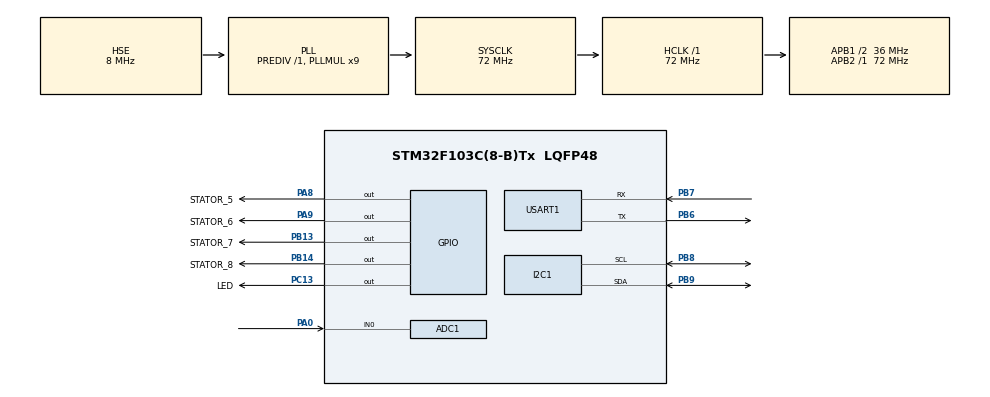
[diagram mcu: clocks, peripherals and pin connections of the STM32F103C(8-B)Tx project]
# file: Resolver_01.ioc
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ADC1.Channel-0\#ChannelRegularConversion=ADC_CHANNEL_0
ADC1.ExternalTrigConv=ADC_EXTERNALTRIGCONV_T3_TRGO
ADC1.NbrOfConversionFlag=1
ADC1.Rank-0\#ChannelRegularConversion=1
ADC1.SamplingTime-0\#ChannelRegularConversion=ADC_SAMPLETIME_1CYCLE_5
ADC1.master=1
Dma.ADC1.1.Direction=DMA_PERIPH_TO_MEMORY
Dma.ADC1.1.Instance=DMA1_Channel1
Dma.ADC1.1.MemDataAlignment=DMA_MDATAALIGN_HALFWORD
Dma.ADC1.1.MemInc=DMA_MINC_ENABLE
Dma.ADC1.1.Mode=DMA_NORMAL
Dma.ADC1.1.PeriphDataAlignment=DMA_PDATAALIGN_HALFWORD
Dma.ADC1.1.PeriphInc=DMA_PINC_DISABLE
Dma.ADC1.1.Priority=DMA_PRIORITY_LOW
Dma.Request0=USART1_TX
Dma.Request1=ADC1
Dma.USART1_TX.0.Direction=DMA_MEMORY_TO_PERIPH
Dma.USART1_TX.0.Instance=DMA1_Channel4
Dma.USART1_TX.0.MemDataAlignment=DMA_MDATAALIGN_BYTE
Dma.USART1_TX.0.MemInc=DMA_MINC_ENABLE
Dma.USART1_TX.0.Mode=DMA_NORMAL
Dma.USART1_TX.0.PeriphDataAlignment=DMA_PDATAALIGN_BYTE
Dma.USART1_TX.0.PeriphInc=DMA_PINC_DISABLE
Dma.USART1_TX.0.Priority=DMA_PRIORITY_LOW
Mcu.Family=STM32F1
Mcu.Name=STM32F103C(8-B)Tx
Mcu.Package=LQFP48
NVIC.DMA1_Channel1_IRQn=true\:0\:0\:false\:false\:true\:false\:true
NVIC.DMA1_Channel4_IRQn=true\:0\:0\:false\:false\:true\:false\:true
NVIC.PriorityGroup=NVIC_PRIORITYGROUP_4
NVIC.TIM2_IRQn=true\:0\:0\:false\:false\:true\:true\:true
NVIC.USART1_IRQn=true\:0\:0\:false\:false\:true\:true\:true
PA0-WKUP.Signal=ADCx_IN0
PA13.Mode=Serial_Wire
PA13.Signal=SYS_JTMS-SWDIO
PA14.Mode=Serial_Wire
PA14.Signal=SYS_JTCK-SWCLK
PA8.GPIO_Label=STATOR_5
PA8.Signal=GPIO_Output
PA9.GPIO_Label=STATOR_6
PA9.Signal=GPIO_Output
PB13.GPIO_Label=STATOR_7
PB13.Signal=GPIO_Output
PB14.GPIO_Label=STATOR_8
PB14.Signal=GPIO_Output
PB6.Mode=Asynchronous
PB6.Signal=USART1_TX
PB7.Mode=Asynchronous
PB7.Signal=USART1_RX
PB8.Mode=I2C
PB8.Signal=I2C1_SCL
PB9.Mode=I2C
PB9.Signal=I2C1_SDA
PC13-TAMPER-RTC.GPIO_Label=LED
PC13-TAMPER-RTC.Signal=GPIO_Output
PD0-OSC_IN.Mode=HSE-External-Oscillator
PD0-OSC_IN.Signal=RCC_OSC_IN
PD1-OSC_OUT.Mode=HSE-External-Oscillator
PD1-OSC_OUT.Signal=RCC_OSC_OUT
ProjectManager.HeapSize=0x00
ProjectManager.StackSize=0x400
ProjectManager.TargetToolchain=EWARM V8.32
RCC.ADCPresc=RCC_ADCPCLK2_DIV6
RCC.AHBFreq_Value=72000000
RCC.APB1CLKDivider=RCC_HCLK_DIV2
RCC.APB1Freq_Value=36000000
RCC.APB1TimFreq_Value=72000000
RCC.APB2Freq_Value=72000000
RCC.APB2TimFreq_Value=72000000
RCC.HCLKFreq_Value=72000000
RCC.PLLMUL=RCC_PLL_MUL9
RCC.PLLSourceVirtual=RCC_PLLSOURCE_HSE
RCC.SYSCLKFreq_VALUE=72000000
RCC.SYSCLKSource=RCC_SYSCLKSOURCE_PLLCLK
RCC.USBFreq_Value=72000000
SH.ADCx_IN0.0=ADC1_IN0,IN0
TIM2.Period=1800
TIM3.Period=144
TIM3.TIM_MasterOutputTrigger=TIM_TRGO_UPDATE
USART1.VirtualMode=VM_ASYNC
VP_TIM2_VS_ClockSourceINT.Mode=Internal
VP_TIM3_VS_ClockSourceINT.Mode=Internal
board=custom

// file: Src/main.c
/* USER CODE BEGIN Header */
/**
  ******************************************************************************
  * @file           : main.c
  * @brief          : Main program body
  ******************************************************************************
  * @attention
  *
  * <h2><center>&copy; Copyright (c) 2020 STMicroelectronics.
  * All rights reserved.</center></h2>
  *
  * This software component is licensed by ST under BSD 3-Clause license,
  * the "License"; You may not use this file except in compliance with the
  * License. You may obtain a copy of the License at:
  *                        opensource.org/licenses/BSD-3-Clause
  *
  ******************************************************************************
  */
/* USER CODE END Header */

#include "main.h"

/* USER CODE BEGIN Includes */
#include "resolver.h"
/* USER CODE END Includes */

ADC_HandleTypeDef hadc1;
DMA_HandleTypeDef hdma_adc1;

I2C_HandleTypeDef hi2c1;

TIM_HandleTypeDef htim2;
TIM_HandleTypeDef htim3;

UART_HandleTypeDef huart1;
DMA_HandleTypeDef hdma_usart1_tx;

void SystemClock_Config(void);
static void MX_GPIO_Init(void);
static void MX_DMA_Init(void);
static void MX_ADC1_Init(void);
static void MX_I2C1_Init(void);
static void MX_TIM2_Init(void);
static void MX_USART1_UART_Init(void);
static void MX_TIM3_Init(void);

int main(void)
{

  /* MCU Configuration--------------------------------------------------------*/

  /* Reset of all peripherals, Initializes the Flash interface and the Systick. */
  HAL_Init();

  /* Configure the system clock */
  SystemClock_Config();

  /* Initialize all configured peripherals */
  MX_GPIO_Init();
  MX_DMA_Init();
  MX_ADC1_Init();
  MX_I2C1_Init();
  MX_TIM2_Init();
  MX_USART1_UART_Init();
  MX_TIM3_Init();

  /* Infinite loop */
  /* USER CODE BEGIN WHILE */
  HAL_TIM_Base_Start_IT(&htim2);                                                // 40 kHz resolver exitation
  HAL_TIM_Base_Start_IT(&htim3);                                                // 500 kHz start ADC

  while (1)
  {
    /* USER CODE END WHILE */
    /* USER CODE BEGIN 3 */
    angle_calculate();
  }
  /* USER CODE END 3 */
}

void SystemClock_Config(void)
{
  RCC_OscInitTypeDef RCC_OscInitStruct = {0};
  RCC_ClkInitTypeDef RCC_ClkInitStruct = {0};
  RCC_PeriphCLKInitTypeDef PeriphClkInit = {0};

  /** Initializes the CPU, AHB and APB busses clocks
  */
  RCC_OscInitStruct.OscillatorType = RCC_OSCILLATORTYPE_HSE;
  RCC_OscInitStruct.HSEState = RCC_HSE_ON;
  RCC_OscInitStruct.HSEPredivValue = RCC_HSE_PREDIV_DIV1;
  RCC_OscInitStruct.HSIState = RCC_HSI_ON;
  RCC_OscInitStruct.PLL.PLLState = RCC_PLL_ON;
  RCC_OscInitStruct.PLL.PLLSource = RCC_PLLSOURCE_HSE;
  RCC_OscInitStruct.PLL.PLLMUL = RCC_PLL_MUL9;
  if (HAL_RCC_OscConfig(&RCC_OscInitStruct) != HAL_OK)
  {
    Error_Handler();
  }
  /** Initializes the CPU, AHB and APB busses clocks
  */
  RCC_ClkInitStruct.ClockType = RCC_CLOCKTYPE_HCLK|RCC_CLOCKTYPE_SYSCLK
                              |RCC_CLOCKTYPE_PCLK1|RCC_CLOCKTYPE_PCLK2;
  RCC_ClkInitStruct.SYSCLKSource = RCC_SYSCLKSOURCE_PLLCLK;
  RCC_ClkInitStruct.AHBCLKDivider = RCC_SYSCLK_DIV1;
  RCC_ClkInitStruct.APB1CLKDivider = RCC_HCLK_DIV2;
  RCC_ClkInitStruct.APB2CLKDivider = RCC_HCLK_DIV1;

  if (HAL_RCC_ClockConfig(&RCC_ClkInitStruct, FLASH_LATENCY_2) != HAL_OK)
  {
    Error_Handler();
  }
  PeriphClkInit.PeriphClockSelection = RCC_PERIPHCLK_ADC;
  PeriphClkInit.AdcClockSelection = RCC_ADCPCLK2_DIV6;
  if (HAL_RCCEx_PeriphCLKConfig(&PeriphClkInit) != HAL_OK)
  {
    Error_Handler();
  }
}

static void MX_ADC1_Init(void)
{

  ADC_ChannelConfTypeDef sConfig = {0};

  /** Common config
  */
  hadc1.Instance = ADC1;
  hadc1.Init.ScanConvMode = ADC_SCAN_DISABLE;
  hadc1.Init.ContinuousConvMode = DISABLE;
  hadc1.Init.DiscontinuousConvMode = DISABLE;
  hadc1.Init.ExternalTrigConv = ADC_EXTERNALTRIGCONV_T3_TRGO;
  hadc1.Init.DataAlign = ADC_DATAALIGN_RIGHT;
  hadc1.Init.NbrOfConversion = 1;
  if (HAL_ADC_Init(&hadc1) != HAL_OK)
  {
    Error_Handler();
  }
  /** Configure Regular Channel
  */
  sConfig.Channel = ADC_CHANNEL_0;
  sConfig.Rank = ADC_REGULAR_RANK_1;
  sConfig.SamplingTime = ADC_SAMPLETIME_1CYCLE_5;
  if (HAL_ADC_ConfigChannel(&hadc1, &sConfig) != HAL_OK)
  {
    Error_Handler();
  }

}

static void MX_I2C1_Init(void)
{

  hi2c1.Instance = I2C1;
  hi2c1.Init.ClockSpeed = 100000;
  hi2c1.Init.DutyCycle = I2C_DUTYCYCLE_2;
  hi2c1.Init.OwnAddress1 = 0;
  hi2c1.Init.AddressingMode = I2C_ADDRESSINGMODE_7BIT;
  hi2c1.Init.DualAddressMode = I2C_DUALADDRESS_DISABLE;
  hi2c1.Init.OwnAddress2 = 0;
  hi2c1.Init.GeneralCallMode = I2C_GENERALCALL_DISABLE;
  hi2c1.Init.NoStretchMode = I2C_NOSTRETCH_DISABLE;
  if (HAL_I2C_Init(&hi2c1) != HAL_OK)
  {
    Error_Handler();
  }

}

static void MX_TIM2_Init(void)
{

  TIM_ClockConfigTypeDef sClockSourceConfig = {0};
  TIM_MasterConfigTypeDef sMasterConfig = {0};

  htim2.Instance = TIM2;
  htim2.Init.Prescaler = 0;
  htim2.Init.CounterMode = TIM_COUNTERMODE_UP;
  htim2.Init.Period = 1800;
  htim2.Init.ClockDivision = TIM_CLOCKDIVISION_DIV1;
  htim2.Init.AutoReloadPreload = TIM_AUTORELOAD_PRELOAD_DISABLE;
  if (HAL_TIM_Base_Init(&htim2) != HAL_OK)
  {
    Error_Handler();
  }
  sClockSourceConfig.ClockSource = TIM_CLOCKSOURCE_INTERNAL;
  if (HAL_TIM_ConfigClockSource(&htim2, &sClockSourceConfig) != HAL_OK)
  {
    Error_Handler();
  }
  sMasterConfig.MasterOutputTrigger = TIM_TRGO_RESET;
  sMasterConfig.MasterSlaveMode = TIM_MASTERSLAVEMODE_DISABLE;
  if (HAL_TIMEx_MasterConfigSynchronization(&htim2, &sMasterConfig) != HAL_OK)
  {
    Error_Handler();
  }

}

static void MX_TIM3_Init(void)
{

  TIM_ClockConfigTypeDef sClockSourceConfig = {0};
  TIM_MasterConfigTypeDef sMasterConfig = {0};

  htim3.Instance = TIM3;
  htim3.Init.Prescaler = 0;
  htim3.Init.CounterMode = TIM_COUNTERMODE_UP;
  htim3.Init.Period = 72;
  htim3.Init.ClockDivision = TIM_CLOCKDIVISION_DIV1;
  htim3.Init.AutoReloadPreload = TIM_AUTORELOAD_PRELOAD_DISABLE;
  if (HAL_TIM_Base_Init(&htim3) != HAL_OK)
  {
    Error_Handler();
  }
  sClockSourceConfig.ClockSource = TIM_CLOCKSOURCE_INTERNAL;
  if (HAL_TIM_ConfigClockSource(&htim3, &sClockSourceConfig) != HAL_OK)
  {
    Error_Handler();
  }
  sMasterConfig.MasterOutputTrigger = TIM_TRGO_UPDATE;
  sMasterConfig.MasterSlaveMode = TIM_MASTERSLAVEMODE_DISABLE;
  if (HAL_TIMEx_MasterConfigSynchronization(&htim3, &sMasterConfig) != HAL_OK)
  {
    Error_Handler();
  }

}

static void MX_USART1_UART_Init(void)
{

  huart1.Instance = USART1;
  huart1.Init.BaudRate = 115200;
  huart1.Init.WordLength = UART_WORDLENGTH_8B;
  huart1.Init.StopBits = UART_STOPBITS_1;
  huart1.Init.Parity = UART_PARITY_NONE;
  huart1.Init.Mode = UART_MODE_TX_RX;
  huart1.Init.HwFlowCtl = UART_HWCONTROL_NONE;
  huart1.Init.OverSampling = UART_OVERSAMPLING_16;
  if (HAL_UART_Init(&huart1) != HAL_OK)
  {
    Error_Handler();
  }

}

static void MX_DMA_Init(void)
{

  /* DMA controller clock enable */
  __HAL_RCC_DMA1_CLK_ENABLE();

  /* DMA interrupt init */
  /* DMA1_Channel1_IRQn interrupt configuration */
  HAL_NVIC_SetPriority(DMA1_Channel1_IRQn, 0, 0);
  HAL_NVIC_EnableIRQ(DMA1_Channel1_IRQn);
  /* DMA1_Channel4_IRQn interrupt configuration */
  HAL_NVIC_SetPriority(DMA1_Channel4_IRQn, 0, 0);
  HAL_NVIC_EnableIRQ(DMA1_Channel4_IRQn);

}

static void MX_GPIO_Init(void)
{
  GPIO_InitTypeDef GPIO_InitStruct = {0};

  /* GPIO Ports Clock Enable */
  __HAL_RCC_GPIOC_CLK_ENABLE();
  __HAL_RCC_GPIOD_CLK_ENABLE();
  __HAL_RCC_GPIOA_CLK_ENABLE();
  __HAL_RCC_GPIOB_CLK_ENABLE();

  /*Configure GPIO pin Output Level */
  HAL_GPIO_WritePin(LED_GPIO_Port, LED_Pin, GPIO_PIN_RESET);

  /*Configure GPIO pin Output Level */
  HAL_GPIO_WritePin(GPIOB, STATOR_7_Pin|STATOR_8_Pin, GPIO_PIN_RESET);

  /*Configure GPIO pin Output Level */
  HAL_GPIO_WritePin(GPIOA, STATOR_5_Pin|STATOR_6_Pin, GPIO_PIN_RESET);

  /*Configure GPIO pin : LED_Pin */
  GPIO_InitStruct.Pin = LED_Pin;
  GPIO_InitStruct.Mode = GPIO_MODE_OUTPUT_PP;
  GPIO_InitStruct.Pull = GPIO_NOPULL;
  GPIO_InitStruct.Speed = GPIO_SPEED_FREQ_LOW;
  HAL_GPIO_Init(LED_GPIO_Port, &GPIO_InitStruct);

  /*Configure GPIO pins : STATOR_7_Pin STATOR_8_Pin */
  GPIO_InitStruct.Pin = STATOR_7_Pin|STATOR_8_Pin;
  GPIO_InitStruct.Mode = GPIO_MODE_OUTPUT_PP;
  GPIO_InitStruct.Pull = GPIO_NOPULL;
  GPIO_InitStruct.Speed = GPIO_SPEED_FREQ_LOW;
  HAL_GPIO_Init(GPIOB, &GPIO_InitStruct);

  /*Configure GPIO pins : STATOR_5_Pin STATOR_6_Pin */
  GPIO_InitStruct.Pin = STATOR_5_Pin|STATOR_6_Pin;
  GPIO_InitStruct.Mode = GPIO_MODE_OUTPUT_PP;
  GPIO_InitStruct.Pull = GPIO_NOPULL;
  GPIO_InitStruct.Speed = GPIO_SPEED_FREQ_LOW;
  HAL_GPIO_Init(GPIOA, &GPIO_InitStruct);

}

void Error_Handler(void)
{
}

/************************ (C) COPYRIGHT STMicroelectronics *****END OF FILE****/
